# AT32UC3A4128S device description
Architecture: AVR32_UC3; Family: AVR UC3
Registers are 32-bit, read-write, reset 0x0 unless marked. A register's access mark holds for its fields unless they carry their own. Offsets are from the block's base; [hi:lo] are bit positions; lines under a group give offsets from that group; {n}, {i} and the like mark numbered series; 'fields as' and 'values as' point back to an identical list.

## MSI — Memory Stick Interface
Instances: MSI 0xfffe8000
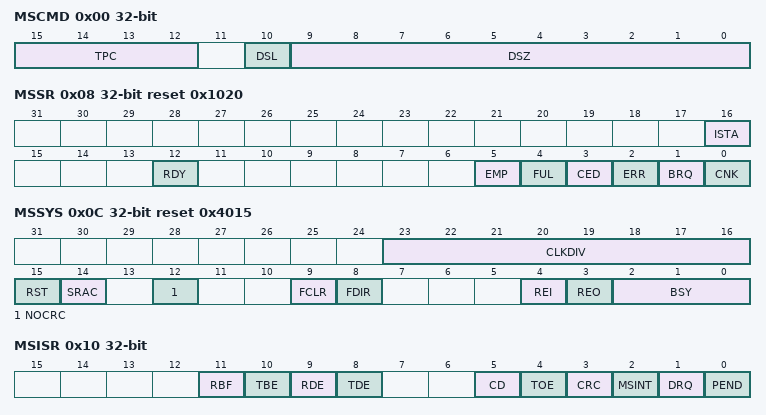
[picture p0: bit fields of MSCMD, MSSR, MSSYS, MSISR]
0x00 MSCMD — Command register
  [15:12] TPC
  [10] DSL
  [9:0] DSZ — Data size
0x04 MSDAT reset 0x4C004C00 — Data register
0x08 MSSR ro reset 0x1020 — Status register
  [16] ISTA, [12] RDY, [5] EMP, [4] FUL, [3] CED, [2] ERR, [1] BRQ, [0] CNK
0x0C MSSYS reset 0x4015 — System register
  [23:16] CLKDIV, [15] RST, [14] SRAC, [12] NOCRC, [9] FCLR, [8] FDIR, [4] REI, [3] REO, [2:0] BSY
0x10 MSISR ro — Interrupt Status register
  [11] RBF, [10] TBE, [9] RDE, [8] TDE, [5] CD, [4] TOE, [3] CRC, [2] MSINT, [1] DRQ, [0] PEND
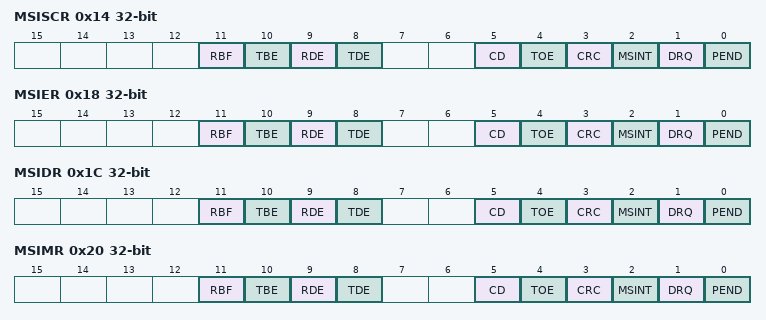
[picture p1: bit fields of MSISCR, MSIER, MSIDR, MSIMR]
0x14 MSISCR wo — Interrupt Status Clear register
  fields as MSISR
0x18 MSIER wo — Interrupt Enable register
  fields as MSISR
0x1C MSIDR wo — Interrupt Disable register
  fields as MSISR
0x20 MSIMR ro — Interrupt Mask register
  fields as MSISR
0x24 VERSION ro reset 0x210
  [11:0] VERSION — MSI Version

## PDCA — Peripheral DMA Controller
Instances: PDCA 0xffff0000
{0x0+0x40*i} channel[{i}] (i=0..31) group
  0x00 MAR — Memory Address Register
    [31:0] MADDR — Memory Address
  0x04 PSR — Peripheral Select Register
    [7:0] PID — Peripheral Identifier
  0x08 TCR — Transfer Counter Register
    [15:0] TCV — Transfer Counter Value
  0x0C MARR — Memory Address Reload Register
    [31:0] MARV — Memory Address Reload Value
  0x10 TCRR — Transfer Counter Reload Register
    [15:0] TCRV — Transfer Counter Reload Value
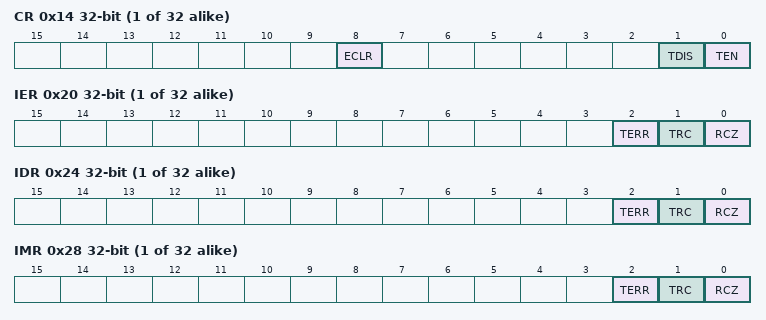
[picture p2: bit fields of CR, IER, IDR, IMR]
  0x14 CR wo — Control Register
    [8] ECLR — Error Clear
    [1] TDIS — Transfer Disable
    [0] TEN — Transfer Enable
  0x18 MR — Mode Register
    [1:0] SIZE — Transfer size
      0=Byte; 1=Half_Word; 2=Word
  0x1C SR ro — Status Register
    [0] TEN — Transfer Enabled
  0x20 IER wo — Interrupt Enable Register
    [2] TERR — Transfer Error
    [1] TRC — Transfer Complete
    [0] RCZ — Reload Counter Zero
  0x24 IDR wo — Interrupt Disable Register
    fields as channel[0].IER
  0x28 IMR ro — Interrupt Mask Register
    fields as channel[0].IER
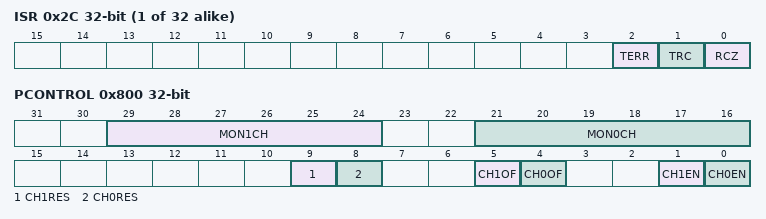
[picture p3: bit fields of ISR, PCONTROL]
  0x2C ISR ro — Interrupt Status Register
    fields as channel[0].IER
0x800 PCONTROL — Performance Control Register
  [29:24] MON1CH — PDCA Channel to monitor with counter 1
  [21:16] MON0CH — PDCA Channel to monitor with counter 0
  [9] CH1RES — Channel 1 counter reset
  [8] CH0RES — Channel 0 counter reset
  [5] CH1OF — Channel 1 overflow freeze
  [4] CH0OF — Channel 0 Overflow Freeze
  [1] CH1EN — Channel 1 Enabled.
  [0] CH0EN — Channel 0 Enabled
0x804 PRDATA0 ro — Channel 0 Read Data Cycles
  [31:0] DATA — Data Cycles Counted Since Last reset
0x808 PRSTALL0 ro — Channel 0 Read Stall Cycles
  [31:0] STALL — Stall Cycles counted since last reset
0x80C PRLAT0 ro — Channel 0 Read Max Latency
  [15:0] LAT — Maximum Transfer Initiation cycles counted since last reset
0x810 PWDATA0 ro — Channel 0 Write Data Cycles
  [31:0] DATA — Data Cycles Counted since last Reset
0x814 PWSTALL0 ro — Channel 0 Write Stall Cycles
  [31:0] STALL — Stall cycles counted since last reset
0x818 PWLAT0 ro — Channel0 Write Max Latency
  [15:0] LAT — Maximum transfer initiation cycles counted since last reset
0x81C PRDATA1 ro — Channel 1 Read Data Cycles
  [31:0] DATA — Data Cycles Counted Since Last reset
0x820 PRSTALL1 ro — Channel Read Stall Cycles
  [31:0] STALL — Stall Cycles Counted since last reset
0x824 PRLAT1 ro — Channel 1 Read Max Latency
  [15:0] LAT — Maximum Transfer initiation cycles counted since last reset
0x828 PWDATA1 ro — Channel 1 Write Data Cycles
  [31:0] DATA — Data cycles Counted Since last reset
0x82C PWSTALL1 ro — Channel 1 Write stall Cycles
  [31:0] STALL — Stall cycles counted since last reset
0x830 PWLAT1 ro — Channel 1 Read Max Latency
  fields as PWLAT0
0x834 VERSION ro reset 0x110
